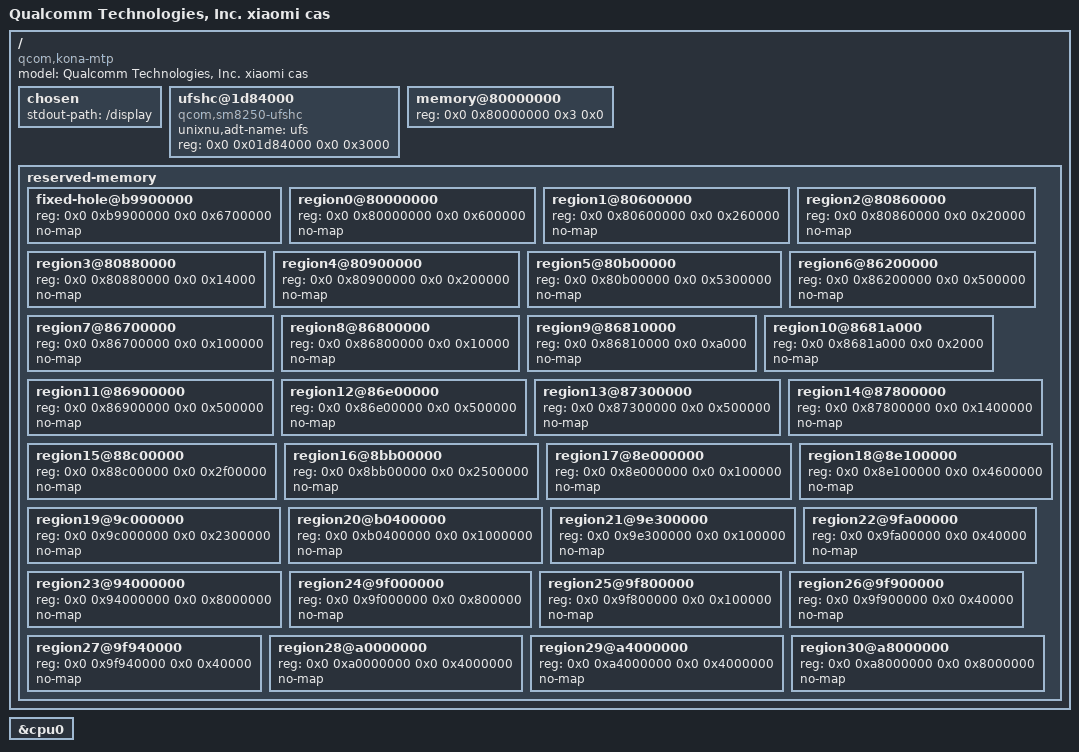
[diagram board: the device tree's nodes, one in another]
// SPDX-License-Identifier: BSD-2-Clause-Patent
/dts-v1/;
/include/ "sm8250.dtsi"

/ {
    model = "Qualcomm Technologies, Inc. xiaomi cas";
    compatible = "qcom,kona-mtp", "qcom,kona", "qcom,mtp";
    chosen { stdout-path = "/display"; };
    // UFS host controller: the boot chain reads boot.img from it, so the ABL hands the
    // controller over with clocks gated on and the PHY trained (same takeover the sheng/umi
    // ports rely on). Node mirrors the stock DTB2 ufshc@1d84000 definition; XNU's
    // ShengUfs/NativeUfs-alioth personality matches "qcom,sm8250-ufshc".
    ufshc@1d84000 {
        unixnu,adt-name = "ufs";
        compatible = "qcom,sm8250-ufshc", "qcom,ufshc";
        reg = <0x0 0x01d84000 0x0 0x3000>;
    };
    // Fix (cas-bringup §3.9): ADT handoff requires ONE contiguous DRAM range.
    // Merged: [0x80000000, 0x380000000) = 12 GiB; the 103 MiB hole is reserved below.
    memory@80000000 {
        device_type = "memory";
        reg = <0x0 0x80000000 0x3 0x0>;
    };
    reserved-memory {
        #address-cells = <2>;
        #size-cells = <2>;
        ranges;
        fixed-hole@b9900000 {
            reg = <0x0 0xb9900000 0x0 0x6700000>;
            no-map;
        };
        region0@80000000 {
            reg = <0x0 0x80000000 0x0 0x600000>;
            no-map;
        };
        region1@80600000 {
            reg = <0x0 0x80600000 0x0 0x260000>;
            no-map;
        };
        region2@80860000 {
            reg = <0x0 0x80860000 0x0 0x20000>;
            no-map;
        };
        region3@80880000 {
            reg = <0x0 0x80880000 0x0 0x14000>;
            no-map;
        };
        region4@80900000 {
            reg = <0x0 0x80900000 0x0 0x200000>;
            no-map;
        };
        region5@80b00000 {
            reg = <0x0 0x80b00000 0x0 0x5300000>;
            no-map;
        };
        region6@86200000 {
            reg = <0x0 0x86200000 0x0 0x500000>;
            no-map;
        };
        region7@86700000 {
            reg = <0x0 0x86700000 0x0 0x100000>;
            no-map;
        };
        region8@86800000 {
            reg = <0x0 0x86800000 0x0 0x10000>;
            no-map;
        };
        region9@86810000 {
            reg = <0x0 0x86810000 0x0 0xa000>;
            no-map;
        };
        region10@8681a000 {
            reg = <0x0 0x8681a000 0x0 0x2000>;
            no-map;
        };
        region11@86900000 {
            reg = <0x0 0x86900000 0x0 0x500000>;
            no-map;
        };
        region12@86e00000 {
            reg = <0x0 0x86e00000 0x0 0x500000>;
            no-map;
        };
        region13@87300000 {
            reg = <0x0 0x87300000 0x0 0x500000>;
            no-map;
        };
        region14@87800000 {
            reg = <0x0 0x87800000 0x0 0x1400000>;
            no-map;
        };
        region15@88c00000 {
            reg = <0x0 0x88c00000 0x0 0x2f00000>;
            no-map;
        };
        region16@8bb00000 {
            reg = <0x0 0x8bb00000 0x0 0x2500000>;
            no-map;
        };
        region17@8e000000 {
            reg = <0x0 0x8e000000 0x0 0x100000>;
            no-map;
        };
        region18@8e100000 {
            reg = <0x0 0x8e100000 0x0 0x4600000>;
            no-map;
        };
        region19@9c000000 {
            reg = <0x0 0x9c000000 0x0 0x2300000>;
            no-map;
        };
        region20@b0400000 {
            reg = <0x0 0xb0400000 0x0 0x1000000>;
            no-map;
        };
        region21@9e300000 {
            reg = <0x0 0x9e300000 0x0 0x100000>;
            no-map;
        };
        region22@9fa00000 {
            reg = <0x0 0x9fa00000 0x0 0x40000>;
            no-map;
        };
        region23@94000000 {
            reg = <0x0 0x94000000 0x0 0x8000000>;
            no-map;
        };
        region24@9f000000 {
            reg = <0x0 0x9f000000 0x0 0x800000>;
            no-map;
        };
        region25@9f800000 {
            reg = <0x0 0x9f800000 0x0 0x100000>;
            no-map;
        };
        region26@9f900000 {
            reg = <0x0 0x9f900000 0x0 0x40000>;
            no-map;
        };
        region27@9f940000 {
            reg = <0x0 0x9f940000 0x0 0x40000>;
            no-map;
        };
        region28@a0000000 {
            reg = <0x0 0xa0000000 0x0 0x4000000>;
            no-map;
        };
        region29@a4000000 {
            reg = <0x0 0xa4000000 0x0 0x4000000>;
            no-map;
        };
        region30@a8000000 {
            reg = <0x0 0xa8000000 0x0 0x8000000>;
            no-map;
        };
    };
};

&cpu0 { status = "okay"; };
